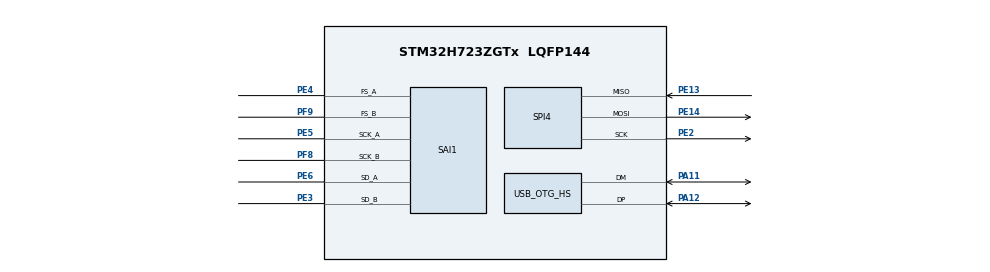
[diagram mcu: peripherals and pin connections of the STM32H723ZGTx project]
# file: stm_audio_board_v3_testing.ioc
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CORTEX_M7.CPU_DCache=Enabled
CORTEX_M7.CPU_ICache=Enabled
CORTEX_M7.default_mode_Activation=1
Mcu.Family=STM32H7
Mcu.Name=STM32H723ZGTx
Mcu.Package=LQFP144
NVIC.OTG_HS_IRQn=true\:0\:0\:false\:false\:true\:false\:true\:true
NVIC.PriorityGroup=NVIC_PRIORITYGROUP_4
PA11.Mode=Device_Only_FS
PA11.Signal=USB_OTG_HS_DM
PA12.Mode=Device_Only_FS
PA12.Signal=USB_OTG_HS_DP
PE13.Mode=Full_Duplex_Master
PE13.Signal=SPI4_MISO
PE14.Mode=Full_Duplex_Master
PE14.Signal=SPI4_MOSI
PE2.Mode=Full_Duplex_Master
PE2.Signal=SPI4_SCK
PE3.Mode=SAI_B_Master
PE3.Signal=SAI1_SD_B
PE4.Mode=SAI_A_Master
PE4.Signal=SAI1_FS_A
PE5.Mode=SAI_A_Master
PE5.Signal=SAI1_SCK_A
PE6.Mode=SAI_A_Master
PE6.Signal=SAI1_SD_A
PF8.Mode=SAI_B_Master
PF8.Signal=SAI1_SCK_B
PF9.Mode=SAI_B_Master
PF9.Signal=SAI1_FS_B
PH0-OSC_IN.Mode=HSE-External-Oscillator
PH0-OSC_IN.Signal=RCC_OSC_IN
PH1-OSC_OUT.Mode=HSE-External-Oscillator
PH1-OSC_OUT.Signal=RCC_OSC_OUT
ProjectManager.HeapSize=0x200
ProjectManager.StackSize=0x400
ProjectManager.TargetToolchain=STM32CubeIDE
RCC.ADCFreq_Value=100000000
RCC.APB1Freq_Value=137500000
RCC.APB2Freq_Value=137500000
RCC.APB3Freq_Value=137500000
RCC.APB4Freq_Value=137500000
RCC.CortexFreq_Value=550000000
RCC.D1PPRE=RCC_APB3_DIV2
RCC.D2PPRE1=RCC_APB1_DIV2
RCC.D2PPRE2=RCC_APB2_DIV2
RCC.D3PPRE=RCC_APB4_DIV2
RCC.DIVM1=2
RCC.DIVM2=2
RCC.DIVN1=44
RCC.DIVN2=16
RCC.DIVP1=1
RCC.DIVQ1=5
RCC.HCLKFreq_Value=275000000
RCC.HPRE=RCC_HCLK_DIV2
RCC.HSE_VALUE=25000000
RCC.PLL2FRACN=0
RCC.PLL3FRACN=0
RCC.PLLFRACN=0
RCC.PLLSourceVirtual=RCC_PLLSOURCE_HSE
RCC.PWR_Regulator_Voltage_Scale=PWR_REGULATOR_VOLTAGE_SCALE0
RCC.SAI1CLockSelection=RCC_SAI1CLKSOURCE_PLL2
RCC.SYSCLKFreq_VALUE=550000000
RCC.SYSCLKSource=RCC_SYSCLKSOURCE_PLLCLK
RCC.USBFreq_Value=110000000
USB_DEVICE.CLASS_NAME_HS=AUDIO
USB_DEVICE.USBD_AUDIO_FREQ=48000
USB_DEVICE.VirtualMode=Audio
USB_DEVICE.VirtualModeHS=Audio_HS
VP_SAI1_VP_$IpInstance_SAIA_SAI_BASIC.Mode=SAI_A_BASIC
VP_SAI1_VP_$IpInstance_SAIB_SAI_BASIC.Mode=SAI_B_BASIC
VP_USB_DEVICE_VS_USB_DEVICE_AUDIO_HS.Mode=AUDIO_HS
board=custom

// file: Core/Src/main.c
/* USER CODE BEGIN Header */
/**
  ******************************************************************************
  * @file           : main.c
  * @brief          : Main program body
  ******************************************************************************
  * @attention
  *
  * Copyright (c) 2024 STMicroelectronics.
  * All rights reserved.
  *
  * This software is licensed under terms that can be found in the LICENSE file
  * in the root directory of this software component.
  * If no LICENSE file comes with this software, it is provided AS-IS.
  *
  ******************************************************************************
  */
/* USER CODE END Header */
#include "main.h"
#include "usb_device.h"

/* USER CODE BEGIN Includes */
#include "usbd_audio.h"

/* USER CODE END Includes */

SAI_HandleTypeDef hsai_BlockA1;
SAI_HandleTypeDef hsai_BlockB1;

SPI_HandleTypeDef hspi4;

void SystemClock_Config(void);
void PeriphCommonClock_Config(void);
static void MPU_Config(void);
static void MX_GPIO_Init(void);
static void MX_SAI1_Init(void);
static void MX_SPI4_Init(void);

int main(void)
{

  /* MPU Configuration--------------------------------------------------------*/
  MPU_Config();
/* Enable the CPU Cache */

  /* Enable I-Cache---------------------------------------------------------*/
  SCB_EnableICache();

  /* Enable D-Cache---------------------------------------------------------*/
  SCB_EnableDCache();

  /* MCU Configuration--------------------------------------------------------*/

  /* Reset of all peripherals, Initializes the Flash interface and the Systick. */
  HAL_Init();

  /* Configure the system clock */
  SystemClock_Config();

/* Configure the peripherals common clocks */
  PeriphCommonClock_Config();

  /* Initialize all configured peripherals */
  MX_GPIO_Init();
  MX_SAI1_Init();
  MX_SPI4_Init();
  MX_USB_DEVICE_Init();

  /* Infinite loop */
  while (1)
  {

  }
}

void SystemClock_Config(void)
{
  RCC_OscInitTypeDef RCC_OscInitStruct = {0};
  RCC_ClkInitTypeDef RCC_ClkInitStruct = {0};

  /** Supply configuration update enable
  */
  HAL_PWREx_ConfigSupply(PWR_LDO_SUPPLY);

  /** Configure the main internal regulator output voltage
  */
  __HAL_PWR_VOLTAGESCALING_CONFIG(PWR_REGULATOR_VOLTAGE_SCALE0);

  while(!__HAL_PWR_GET_FLAG(PWR_FLAG_VOSRDY)) {}

  /** Initializes the RCC Oscillators according to the specified parameters
  * in the RCC_OscInitTypeDef structure.
  */
  RCC_OscInitStruct.OscillatorType = RCC_OSCILLATORTYPE_HSE;
  RCC_OscInitStruct.HSEState = RCC_HSE_ON;
  RCC_OscInitStruct.PLL.PLLState = RCC_PLL_ON;
  RCC_OscInitStruct.PLL.PLLSource = RCC_PLLSOURCE_HSE;
  RCC_OscInitStruct.PLL.PLLM = 2;
  RCC_OscInitStruct.PLL.PLLN = 44;
  RCC_OscInitStruct.PLL.PLLP = 1;
  RCC_OscInitStruct.PLL.PLLQ = 5;
  RCC_OscInitStruct.PLL.PLLR = 2;
  RCC_OscInitStruct.PLL.PLLRGE = RCC_PLL1VCIRANGE_3;
  RCC_OscInitStruct.PLL.PLLVCOSEL = RCC_PLL1VCOWIDE;
  RCC_OscInitStruct.PLL.PLLFRACN = 0;
  if (HAL_RCC_OscConfig(&RCC_OscInitStruct) != HAL_OK)
  {
    Error_Handler();
  }

  /** Initializes the CPU, AHB and APB buses clocks
  */
  RCC_ClkInitStruct.ClockType = RCC_CLOCKTYPE_HCLK|RCC_CLOCKTYPE_SYSCLK
                              |RCC_CLOCKTYPE_PCLK1|RCC_CLOCKTYPE_PCLK2
                              |RCC_CLOCKTYPE_D3PCLK1|RCC_CLOCKTYPE_D1PCLK1;
  RCC_ClkInitStruct.SYSCLKSource = RCC_SYSCLKSOURCE_PLLCLK;
  RCC_ClkInitStruct.SYSCLKDivider = RCC_SYSCLK_DIV1;
  RCC_ClkInitStruct.AHBCLKDivider = RCC_HCLK_DIV2;
  RCC_ClkInitStruct.APB3CLKDivider = RCC_APB3_DIV2;
  RCC_ClkInitStruct.APB1CLKDivider = RCC_APB1_DIV2;
  RCC_ClkInitStruct.APB2CLKDivider = RCC_APB2_DIV2;
  RCC_ClkInitStruct.APB4CLKDivider = RCC_APB4_DIV2;

  if (HAL_RCC_ClockConfig(&RCC_ClkInitStruct, FLASH_LATENCY_3) != HAL_OK)
  {
    Error_Handler();
  }
}

void PeriphCommonClock_Config(void)
{
  RCC_PeriphCLKInitTypeDef PeriphClkInitStruct = {0};

  /** Initializes the peripherals clock
  */
  PeriphClkInitStruct.PeriphClockSelection = RCC_PERIPHCLK_SAI1;
  PeriphClkInitStruct.PLL2.PLL2M = 2;
  PeriphClkInitStruct.PLL2.PLL2N = 16;
  PeriphClkInitStruct.PLL2.PLL2P = 2;
  PeriphClkInitStruct.PLL2.PLL2Q = 2;
  PeriphClkInitStruct.PLL2.PLL2R = 2;
  PeriphClkInitStruct.PLL2.PLL2RGE = RCC_PLL2VCIRANGE_3;
  PeriphClkInitStruct.PLL2.PLL2VCOSEL = RCC_PLL2VCOWIDE;
  PeriphClkInitStruct.PLL2.PLL2FRACN = 0;
  PeriphClkInitStruct.Sai1ClockSelection = RCC_SAI1CLKSOURCE_PLL2;
  if (HAL_RCCEx_PeriphCLKConfig(&PeriphClkInitStruct) != HAL_OK)
  {
    Error_Handler();
  }
}

static void MX_SAI1_Init(void)
{

  hsai_BlockA1.Instance = SAI1_Block_A;
  hsai_BlockA1.Init.AudioMode = SAI_MODEMASTER_RX;
  hsai_BlockA1.Init.Synchro = SAI_ASYNCHRONOUS;
  hsai_BlockA1.Init.OutputDrive = SAI_OUTPUTDRIVE_DISABLE;
  hsai_BlockA1.Init.NoDivider = SAI_MASTERDIVIDER_ENABLE;
  hsai_BlockA1.Init.FIFOThreshold = SAI_FIFOTHRESHOLD_EMPTY;
  hsai_BlockA1.Init.AudioFrequency = SAI_AUDIO_FREQUENCY_48K;
  hsai_BlockA1.Init.SynchroExt = SAI_SYNCEXT_DISABLE;
  hsai_BlockA1.Init.MonoStereoMode = SAI_STEREOMODE;
  hsai_BlockA1.Init.CompandingMode = SAI_NOCOMPANDING;
  if (HAL_SAI_InitProtocol(&hsai_BlockA1, SAI_I2S_STANDARD, SAI_PROTOCOL_DATASIZE_32BIT, 8) != HAL_OK)
  {
    Error_Handler();
  }
  hsai_BlockB1.Instance = SAI1_Block_B;
  hsai_BlockB1.Init.AudioMode = SAI_MODEMASTER_TX;
  hsai_BlockB1.Init.Synchro = SAI_ASYNCHRONOUS;
  hsai_BlockB1.Init.OutputDrive = SAI_OUTPUTDRIVE_DISABLE;
  hsai_BlockB1.Init.NoDivider = SAI_MASTERDIVIDER_ENABLE;
  hsai_BlockB1.Init.FIFOThreshold = SAI_FIFOTHRESHOLD_EMPTY;
  hsai_BlockB1.Init.AudioFrequency = SAI_AUDIO_FREQUENCY_48K;
  hsai_BlockB1.Init.SynchroExt = SAI_SYNCEXT_DISABLE;
  hsai_BlockB1.Init.MonoStereoMode = SAI_STEREOMODE;
  hsai_BlockB1.Init.CompandingMode = SAI_NOCOMPANDING;
  hsai_BlockB1.Init.TriState = SAI_OUTPUT_NOTRELEASED;
  if (HAL_SAI_InitProtocol(&hsai_BlockB1, SAI_I2S_STANDARD, SAI_PROTOCOL_DATASIZE_32BIT, 8) != HAL_OK)
  {
    Error_Handler();
  }

}

static void MX_SPI4_Init(void)
{

  /* SPI4 parameter configuration*/
  hspi4.Instance = SPI4;
  hspi4.Init.Mode = SPI_MODE_MASTER;
  hspi4.Init.Direction = SPI_DIRECTION_2LINES;
  hspi4.Init.DataSize = SPI_DATASIZE_4BIT;
  hspi4.Init.CLKPolarity = SPI_POLARITY_LOW;
  hspi4.Init.CLKPhase = SPI_PHASE_1EDGE;
  hspi4.Init.NSS = SPI_NSS_SOFT;
  hspi4.Init.BaudRatePrescaler = SPI_BAUDRATEPRESCALER_2;
  hspi4.Init.FirstBit = SPI_FIRSTBIT_MSB;
  hspi4.Init.TIMode = SPI_TIMODE_DISABLE;
  hspi4.Init.CRCCalculation = SPI_CRCCALCULATION_DISABLE;
  hspi4.Init.CRCPolynomial = 0x0;
  hspi4.Init.NSSPMode = SPI_NSS_PULSE_ENABLE;
  hspi4.Init.NSSPolarity = SPI_NSS_POLARITY_LOW;
  hspi4.Init.FifoThreshold = SPI_FIFO_THRESHOLD_01DATA;
  hspi4.Init.TxCRCInitializationPattern = SPI_CRC_INITIALIZATION_ALL_ZERO_PATTERN;
  hspi4.Init.RxCRCInitializationPattern = SPI_CRC_INITIALIZATION_ALL_ZERO_PATTERN;
  hspi4.Init.MasterSSIdleness = SPI_MASTER_SS_IDLENESS_00CYCLE;
  hspi4.Init.MasterInterDataIdleness = SPI_MASTER_INTERDATA_IDLENESS_00CYCLE;
  hspi4.Init.MasterReceiverAutoSusp = SPI_MASTER_RX_AUTOSUSP_DISABLE;
  hspi4.Init.MasterKeepIOState = SPI_MASTER_KEEP_IO_STATE_DISABLE;
  hspi4.Init.IOSwap = SPI_IO_SWAP_DISABLE;
  if (HAL_SPI_Init(&hspi4) != HAL_OK)
  {
    Error_Handler();
  }

}

static void MX_GPIO_Init(void)
{

  /* GPIO Ports Clock Enable */
  __HAL_RCC_GPIOE_CLK_ENABLE();
  __HAL_RCC_GPIOF_CLK_ENABLE();
  __HAL_RCC_GPIOH_CLK_ENABLE();
  __HAL_RCC_GPIOA_CLK_ENABLE();

}

/* MPU Configuration */

void MPU_Config(void)
{
  MPU_Region_InitTypeDef MPU_InitStruct = {0};

  /* Disables the MPU */
  HAL_MPU_Disable();

  /** Initializes and configures the Region and the memory to be protected
  */
  MPU_InitStruct.Enable = MPU_REGION_ENABLE;
  MPU_InitStruct.Number = MPU_REGION_NUMBER0;
  MPU_InitStruct.BaseAddress = 0x0;
  MPU_InitStruct.Size = MPU_REGION_SIZE_4GB;
  MPU_InitStruct.SubRegionDisable = 0x87;
  MPU_InitStruct.TypeExtField = MPU_TEX_LEVEL0;
  MPU_InitStruct.AccessPermission = MPU_REGION_NO_ACCESS;
  MPU_InitStruct.DisableExec = MPU_INSTRUCTION_ACCESS_DISABLE;
  MPU_InitStruct.IsShareable = MPU_ACCESS_SHAREABLE;
  MPU_InitStruct.IsCacheable = MPU_ACCESS_NOT_CACHEABLE;
  MPU_InitStruct.IsBufferable = MPU_ACCESS_NOT_BUFFERABLE;

  HAL_MPU_ConfigRegion(&MPU_InitStruct);
  /* Enables the MPU */
  HAL_MPU_Enable(MPU_PRIVILEGED_DEFAULT);

}

void Error_Handler(void)
{
  __disable_irq();
  while (1)
  {
  }
}
